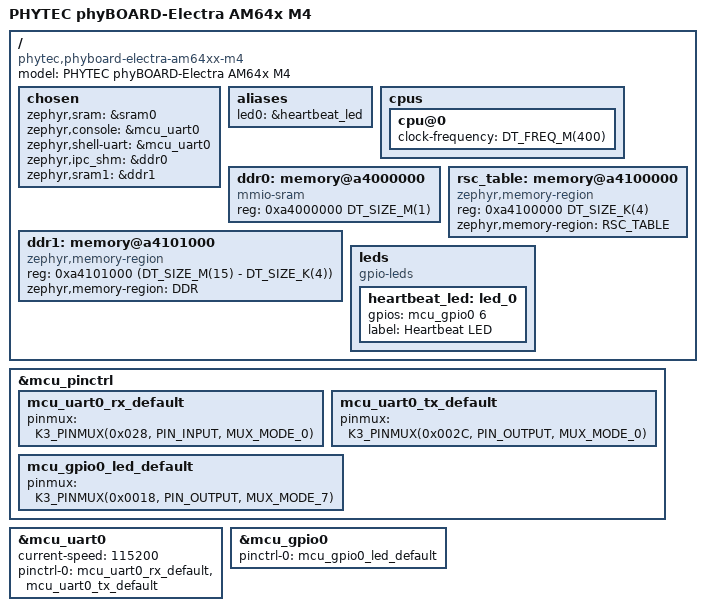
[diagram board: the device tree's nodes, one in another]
/*
 * Copyright (C) 2024 PHYTEC Messtechnik GmbH
 * Author: Daniel Schultz <d.schultz@phytec.de>
 *
 * SPDX-License-Identifier: Apache-2.0
 */

/dts-v1/;

#include <zephyr/dt-bindings/pinctrl/ti-k3-pinctrl.h>
#include <zephyr/dt-bindings/gpio/gpio.h>
#include <ti/am64x_m4.dtsi>

/ {
	model = "PHYTEC phyBOARD-Electra AM64x M4";
	compatible = "phytec,phyboard-electra-am64xx-m4", "ti,am6442";

	chosen {
		zephyr,sram = &sram0;
		zephyr,console = &mcu_uart0;
		zephyr,shell-uart = &mcu_uart0;
		zephyr,ipc_shm = &ddr0;
		zephyr,sram1 = &ddr1;
	};

	aliases {
		led0 = &heartbeat_led;
	};

	cpus {
		cpu@0 {
			status = "okay";
			clock-frequency = <DT_FREQ_M(400)>;
		};
	};

	ddr0: memory@a4000000 {
		compatible = "mmio-sram";
		reg = <0xa4000000 DT_SIZE_M(1)>;
	};

	rsc_table: memory@a4100000 {
		compatible = "zephyr,memory-region", "mmio-sram";
		reg = <0xa4100000 DT_SIZE_K(4)>;
		zephyr,memory-region = "RSC_TABLE";
	};

	ddr1: memory@a4101000 {
		compatible = "zephyr,memory-region", "mmio-sram";
		reg = <0xa4101000 (DT_SIZE_M(15) - DT_SIZE_K(4))>;
		zephyr,memory-region = "DDR";
	};

	leds: leds {
		compatible = "gpio-leds";

		heartbeat_led: led_0 {
			gpios = <&mcu_gpio0 6 GPIO_ACTIVE_HIGH>;
			label = "Heartbeat LED";
		};
	};
};

&mcu_pinctrl {
	status = "okay";

	mcu_uart0_rx_default: mcu_uart0_rx_default {
		pinmux = <K3_PINMUX(0x028, PIN_INPUT, MUX_MODE_0)>;
	};

	mcu_uart0_tx_default: mcu_uart0_tx_default {
		pinmux = <K3_PINMUX(0x002C, PIN_OUTPUT, MUX_MODE_0)>;
	};

	mcu_gpio0_led_default: mcu_gpio0_led_default {
		pinmux = <K3_PINMUX(0x0018, PIN_OUTPUT, MUX_MODE_7)>;
	};
};

&mcu_uart0 {
	current-speed = <115200>;
	pinctrl-0 = <&mcu_uart0_rx_default &mcu_uart0_tx_default>;
	pinctrl-names = "default";
	status = "okay";
};

&mcu_gpio0 {
	pinctrl-0 = <&mcu_gpio0_led_default>;
	pinctrl-names = "default";
	status = "okay";
};
